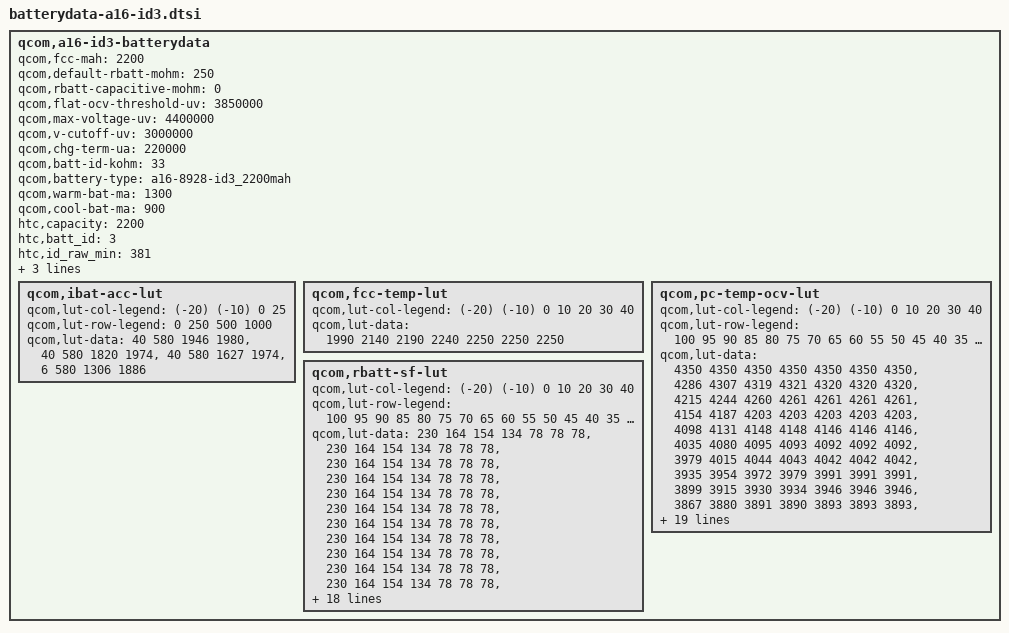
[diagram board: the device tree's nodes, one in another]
/* Copyright (c) 2013, The Linux Foundation. All rights reserved.
 *
 * This program is free software; you can redistribute it and/or modify
 * it under the terms of the GNU General Public License version 2 and
 * only version 2 as published by the Free Software Foundation.
 *
 * This program is distributed in the hope that it will be useful,
 * but WITHOUT ANY WARRANTY; without even the implied warranty of
 * MERCHANTABILITY or FITNESS FOR A PARTICULAR PURPOSE.  See the
 * GNU General Public License for more details.
 */

qcom,a16-id3-batterydata {
	qcom,fcc-mah = <2200>;
	qcom,default-rbatt-mohm = <250>;
	qcom,rbatt-capacitive-mohm = <0>;
	qcom,flat-ocv-threshold-uv = <3850000>;
	qcom,max-voltage-uv = <4400000>;
	qcom,v-cutoff-uv = <3000000>;
	qcom,chg-term-ua = <220000>;
	qcom,batt-id-kohm = <33>;
	qcom,battery-type = "a16-8928-id3_2200mah";
	qcom,warm-bat-ma = <1300>;
	qcom,cool-bat-ma = <900>;
	htc,capacity = <2200>;
	htc,batt_id = <3>;
	htc,id_raw_min = <381>;
	htc,id_raw_max = <510>;
	htc,type = <1>;
	htc,model_name = "ASN";

	qcom,ibat-acc-lut {
		qcom,lut-col-legend = <(-20) (-10) 0 25>;
		qcom,lut-row-legend = <0 250 500 1000>;
		qcom,lut-data = <40 580 1946 1980>,
				<40 580 1820 1974>,
				<40 580 1627 1974>,
				<6 580 1306 1886>;
	};

	qcom,fcc-temp-lut {
		qcom,lut-col-legend = <(-20) (-10) 0 10 20 30 40>;
		qcom,lut-data = <1990 2140 2190 2240 2250 2250 2250>;
	};

	qcom,pc-temp-ocv-lut {
		qcom,lut-col-legend = <(-20) (-10) 0 10 20 30 40>;
		qcom,lut-row-legend = <100 95 90 85 80 75 70 65 60 55 50 45 40 35 30 25 20 15 10 9 8 7 6 5 4 3 2 1 0>;
		qcom,lut-data = <4350 4350 4350 4350 4350 4350 4350>,
				<4286 4307 4319 4321 4320 4320 4320>,
				<4215 4244 4260 4261 4261 4261 4261>,
				<4154 4187 4203 4203 4203 4203 4203>,
				<4098 4131 4148 4148 4146 4146 4146>,
				<4035 4080 4095 4093 4092 4092 4092>,
				<3979 4015 4044 4043 4042 4042 4042>,
				<3935 3954 3972 3979 3991 3991 3991>,
				<3899 3915 3930 3934 3946 3946 3946>,
				<3867 3880 3891 3890 3893 3893 3893>,
				<3842 3849 3857 3856 3858 3858 3858>,
				<3824 3824 3831 3830 3832 3832 3832>,
				<3810 3805 3810 3808 3811 3811 3811>,
				<3797 3792 3792 3791 3793 3793 3793>,
				<3785 3780 3781 3778 3777 3777 3777>,
				<3773 3769 3770 3766 3761 3761 3761>,
				<3759 3754 3755 3749 3742 3742 3742>,
				<3744 3734 3730 3721 3714 3714 3714>,
				<3726 3707 3698 3693 3689 3689 3689>,
				<3722 3703 3694 3685 3680 3680 3680>,
				<3718 3698 3690 3678 3671 3671 3671>,
				<3714 3693 3686 3670 3662 3662 3662>,
				<3711 3689 3681 3663 3653 3653 3653>,
				<3707 3684 3677 3656 3644 3644 3644>,
				<3565 3547 3542 3524 3515 3515 3515>,
				<3424 3411 3406 3393 3387 3387 3387>,
				<3283 3274 3271 3262 3258 3258 3258>,
				<3141 3137 3135 3131 3129 3129 3129>,
				<3000 3000 3000 3000 3000 3000 3000>;
	};

	qcom,rbatt-sf-lut {
		qcom,lut-col-legend = <(-20) (-10) 0 10 20 30 40>;
		qcom,lut-row-legend = <100 95 90 85 80 75 70 65 60 55 50 45 40 35 30 25 20 15 10 9 8 7 6 5 4 3 2 1 0>;
		qcom,lut-data = <230 164 154 134 78 78 78>,
				<230 164 154 134 78 78 78>,
				<230 164 154 134 78 78 78>,
				<230 164 154 134 78 78 78>,
				<230 164 154 134 78 78 78>,
				<230 164 154 134 78 78 78>,
				<230 164 154 134 78 78 78>,
				<230 164 154 134 78 78 78>,
				<230 164 154 134 78 78 78>,
				<230 164 154 134 78 78 78>,
				<230 164 154 134 78 78 78>,
				<230 164 154 134 78 78 78>,
				<230 164 154 134 78 78 78>,
				<230 164 154 134 78 78 78>,
				<230 164 154 134 78 78 78>,
				<230 164 154 134 78 78 78>,
				<230 164 154 134 78 78 78>,
				<230 164 154 134 78 78 78>,
				<230 164 154 134 78 78 78>,
				<230 164 154 134 78 78 78>,
				<230 164 154 134 78 78 78>,
				<230 164 154 134 78 78 78>,
				<230 164 154 134 78 78 78>,
				<230 164 154 134 78 78 78>,
				<230 164 154 134 78 78 78>,
				<230 164 154 134 78 78 78>,
				<230 164 154 134 78 78 78>,
				<230 164 154 134 78 78 78>,
				<230 164 154 134 78 78 78>;
		};
};
